# S1C31W74 register map
Vendor: Epson; Series: S1C31W74; File version: 1.11
CPU: CM0PLUS r0p1, little endian, MPU, no FPU, VTOR, 2 interrupt priority bits
Registers are 16-bit, read-write, reset 0x0 unless marked. A register's access mark holds for its fields unless they carry their own. Offsets are from the block's base; [hi:lo] are bit positions; 'fields as' and 'values as' point back to an identical list.

## USB — USB Controller
Base 0x20400000
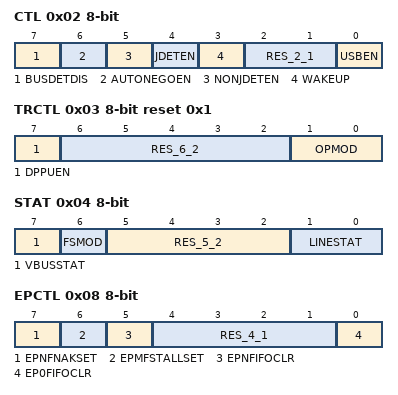
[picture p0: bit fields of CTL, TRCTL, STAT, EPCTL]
0x02 CTL 8-bit — Control Register
  [7] BUSDETDIS — USB Reset and Suspend states auto detect disable
    0=ENABLE (Enable BusDetect); 1=DISABLE (Disable BusDetect)
  [6] AUTONEGOEN — Auto-Negotiation enable
    0=DISABLE; 1=ENABLE
  [5] NONJDETEN write-1-sets — NonJ state detection enable
    0=NON (No effect); 1=ENABLE
  [4] JDETEN write-1-sets — J state detection enable
    0=NON (No effect); 1=ENABLE
  [3] WAKEUP write-1-sets — Send remote wakeup signal (K) to the USB port
    0=NON (No effect); 1=SEND (Send remote wakeup signal)
  [2:1] RES_2_1 ro — Reserved bits
  [0] USBEN — USB enable
    0=DISABLE; 1=ENABLE
0x03 TRCTL 8-bit reset 0x1 — Control Register
  [7] DPPUEN — D+ line pull-up resistor control
    0=DISABLE; 1=ENABLE
  [6:2] RES_6_2 ro — Reserved bits
  [1:0] OPMOD — Transceiver macro operation mode
    0=NORMAL (Normal operation); 1=NON_DRIVING; 2=DIS_BITSTUF_NRZI (Disable bit stuffing and NRZI encoding)
0x04 STAT 8-bit — Status Register
  [7] VBUSSTAT ro — USBVBUS pin status
    0=LOW (VBUS = L); 1=HIGH (VBUS = H)
  [6] FSMOD ro — FS mode support
    1=SUPPORTED (FS mode)
  [5:2] RES_5_2 ro — Reserved bits
  [1:0] LINESTAT ro — USB cable (value received by the FS receiver of the DP/DM) signal status
    0=SE0 (Single Ended Zero state); 1=J (J state); 2=K (K state); 3=SE1 (Single Ended One state)
0x08 EPCTL 8-bit — Endpoint Control Register
  [7] EPNFNAKSET wo write-1-sets — Endpoint ForceNAK bit
    0=NON (No effect); 1=SET (Set all ForceNAK)
  [6] EPMFSTALLSET wo write-1-sets — Endpoint ForceSTALL bit
    0=NON (No effect); 1=SET (Set all ForceSTALL)
  [5] EPNFIFOCLR wo write-1-sets — Endpoint FIFO clear
    0=NON (No effect); 1=CLEAR (Clear FIFO)
  [4:1] RES_4_1 ro — Reserved bits
  [0] EP0FIFOCLR wo write-1-sets — Endpoint EP0 FIFO clear
    0=NON (No effect); 1=CLEAR (Clear EP0 FIFO)
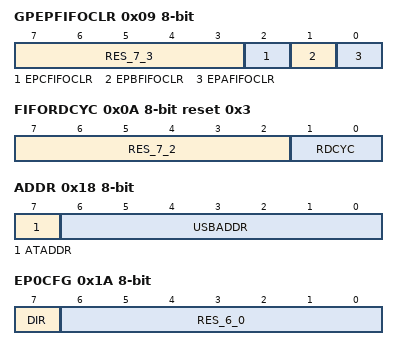
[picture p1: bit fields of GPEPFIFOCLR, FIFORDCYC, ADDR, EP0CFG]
0x09 GPEPFIFOCLR 8-bit — Endpoint Control Register
  [7:3] RES_7_3 ro — Reserved bits
  [2] EPCFIFOCLR wo write-1-sets — Endpoint EPc FIFO clear
    0=NON (No effect); 1=CLEAR (Clear EPc FIFO)
  [1] EPBFIFOCLR wo write-1-sets — Endpoint EPb FIFO clear
    0=NON (No effect); 1=CLEAR (Clear EPb FIFO)
  [0] EPAFIFOCLR wo write-1-sets — Endpoint EPa FIFO clear
    0=NON (No effect); 1=CLEAR (Clear EPa FIFO)
0x0A FIFORDCYC 8-bit reset 0x3 — FIFO Read Cycle Setup Register
  [7:2] RES_7_2 ro — Reserved bits
  [1:0] RDCYC — FIFO read access cycles
    0=1_CYC (1 cycle); 1=2_CYC (2 cycles); 2=3_CYC (3 cycles); 3=4_CYC (4 cycles)
0x0E REV 8-bit ro — Revision Number Register
  [7:0] REVNUM — USB controller revision number
0x10 EP0SETUP0 8-bit ro — EP0 Setup Data Register 0
  [7:0] BMREQTYP — Endpoint EP0 SETUP stage received BmRequestType
0x11 EP0SETUP1 8-bit ro — EP0 Setup Data Register 1
  [7:0] BREQ — Endpoint EP0 SETUP stage received BRequest
0x12 EP0SETUP2 8-bit ro — EP0 Setup Data Register 2
  [7:0] WVAL — Endpoint EP0 SETUP stage received Wvalue
0x13 EP0SETUP3 8-bit ro — EP0 Setup Data Register 3
  [7:0] WVAL — Endpoint EP0 SETUP stage received Wvalue
0x14 EP0SETUP4 8-bit ro — EP0 Setup Data Register 4
  [7:0] WINDX — Endpoint EP0 SETUP stage received WIndex
0x15 EP0SETUP5 8-bit ro — EP0 Setup Data Register 5
  [7:0] WINDX — Endpoint EP0 SETUP stage received WIndex
0x16 EP0SETUP6 8-bit ro — EP0 Setup Data Register 6
  [7:0] WLEN — Endpoint EP0 SETUP stage received WLength
0x17 EP0SETUP7 8-bit ro — EP0 Setup Data Register 3
  [7:0] WLEN — Endpoint EP0 SETUP stage received WLength
0x18 ADDR 8-bit — Address Register
  [7] ATADDR write-1-sets — USB address automatic setup
    0=NON (No effect); 1=AUTO (Auto set address)
  [6:0] USBADDR — USB address
0x1A EP0CFG 8-bit — EP0 Configuration Register
  [7] DIR — Endpoint EP0 transfer direction
    0=OUT (Output); 1=IN (Input)
  [6:0] RES_6_0 ro — Reserved bits
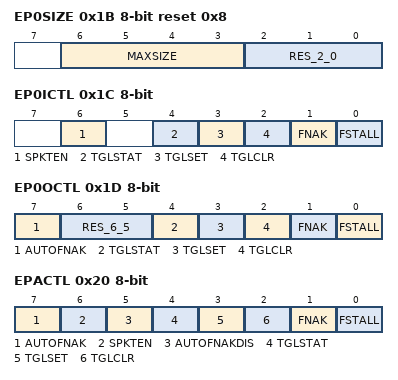
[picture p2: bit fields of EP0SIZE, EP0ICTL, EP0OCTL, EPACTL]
0x1B EP0SIZE 8-bit reset 0x8 — EP0 Configuration Size Register
  [6:3] MAXSIZE — Endpoint EP0 maximum packet size
  [2:0] RES_2_0 ro — Reserved bits
0x1C EP0ICTL 8-bit — EP0 IN Transaction Control Register
  [6] SPKTEN write-1-sets — Endpoint EP0 IN transaction short packet enable
    0=NON (No effect); 1=ENABLE (Enable short packet)
  [4] TGLSTAT ro — Endpoint EP0 IN transaction toggle sequence bit status
  [3] TGLSET wo write-1-sets — Endpoint EP0 IN transaction toggle sequence bit set
    0=NON (No effect); 1=SET (Set toggle sequence bit)
  [2] TGLCLR wo write-1-clears — Endpoint EP0 IN transaction toggle sequence bit clear
    0=NON (No effect); 1=CLEAR (Clear toggle sequence bit)
  [1] FNAK write-1-sets — Endpoint EP0 IN transaction ForceNAK
    0=NON (No effect); 1=FORCE (Force NAK)
  [0] FSTALL write-1-sets — Endpoint EP0 IN transaction ForceSTALL
    0=NON (No effect); 1=FORCE (Force STALL)
0x1D EP0OCTL 8-bit — EP0 OUT Transaction Control Register
  [7] AUTOFNAK write-1-sets — Auto ForceNAK when the OUT transaction of the endpoint EP0 completes normally
    0=NON (No effect); 1=ENABLE (Enable auto ForceNAK)
  [6:5] RES_6_5 ro — Reserved bits
  [4] TGLSTAT ro — Endpoint EP0 OUT transaction toggle sequence bit status
  [3] TGLSET wo write-1-sets — Endpoint EP0 OUT transaction toggle sequence bit set
    0=NON (No effect); 1=SET (Set toggle sequence bit)
  [2] TGLCLR wo write-1-clears — Endpoint EP0 OUT transaction toggle sequence bit clear
    0=NON (No effect); 1=CLEAR (Clear toggle sequence bit)
  [1] FNAK write-1-sets — Endpoint EP0 OUT transaction ForceNAK
    0=NON (No effect); 1=FORCE (Force NAK)
  [0] FSTALL write-1-sets — Endpoint EP0 OUT transaction ForceSTALL
    0=NON (No effect); 1=FORCE (Force STALL)
0x20 EPACTL 8-bit — EPa Control Register
  [7] AUTOFNAK write-1-sets — Auto ForceNAK when the transaction of the endpoint completes normally
    0=NON (No effect); 1=ENABLE (Enable auto ForceNAK)
  [6] SPKTEN write-1-sets — Endpoint IN transaction short packet enable
    0=NON (No effect); 1=ENABLE (Enable short packet)
  [5] AUTOFNAKDIS write-1-sets — Endpoint OUT transaction auto ForceNAK disable
    0=NON (No effect); 1=DISABLE (Disable auto ForceNAK for OUT transaction)
  [4] TGLSTAT ro — Endpoint toggle sequence bit status
  [3] TGLSET wo write-1-sets — Endpoint toggle sequence bit set
    0=NON (No effect); 1=SET (Set toggle sequence bit)
  [2] TGLCLR wo write-1-clears — Endpoint toggle sequence bit clear
    0=NON (No effect); 1=CLEAR (Clear toggle sequence bit)
  [1] FNAK write-1-sets — Endpoint ForceNAK
    0=NON (No effect); 1=FORCE (Force NAK)
  [0] FSTALL write-1-sets — Endpoint ForceSTALL
    0=NON (No effect); 1=FORCE (Force STALL)
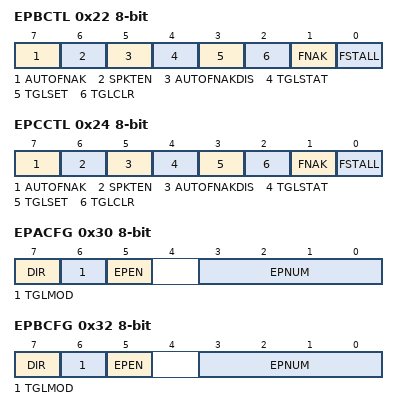
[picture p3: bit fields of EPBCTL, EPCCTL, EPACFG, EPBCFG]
0x22 EPBCTL 8-bit — EPb Control Register
  fields as EPACTL
0x24 EPCCTL 8-bit — EPc Control Register
  fields as EPACTL
0x30 EPACFG 8-bit — EPa Configuration Register
  [7] DIR — Endpoint transfer direction
    0=OUT (Output); 1=IN (Input)
  [6] TGLMOD — Endpoint toggle sequence operation mode
    0=NORMAL (Normal Toggle); 1=ALWAYS (Always Toggle)
  [5] EPEN — Endpoint enable
    0=DISABLE (Disable endPoint); 1=ENABLE (Enable endPoint)
  [3:0] EPNUM — Endpoint number
0x31 EPAMAXSZ 8-bit — EPa Size Register
  [6:0] MAXSIZE — Endpoint maximum packet size
0x32 EPBCFG 8-bit — EPb Configuration Register
  fields as EPACFG
0x33 EPBMAXSZ 8-bit — EPb Size Register
  [6:0] MAXSIZE — Endpoint maximum packet size
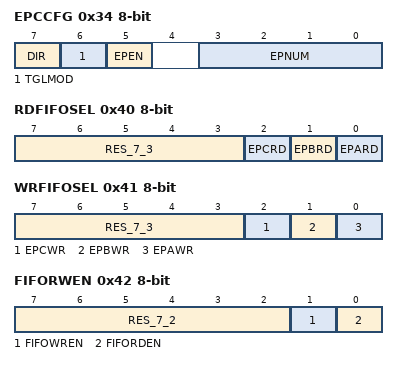
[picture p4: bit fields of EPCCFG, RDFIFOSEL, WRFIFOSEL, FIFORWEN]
0x34 EPCCFG 8-bit — EPc Configuration Register
  fields as EPACFG
0x35 EPCMAXSZ 8-bit — EPC Size Register
  [6:0] MAXSIZE — Endpoint maximum packet size
0x40 RDFIFOSEL 8-bit — Read FIFO Select Register
  [7:3] RES_7_3 ro — Reserved bits
  [2] EPCRD write-1-sets — Endpoint EPc FIFO read select
    0=NON (No effect); 1=SELECT (Select endpoint EPc for FIFO read)
  [1] EPBRD write-1-sets — Endpoint EPb FIFO read select
    0=NON (No effect); 1=SELECT (Select endpoint EPb for FIFO read)
  [0] EPARD write-1-sets — Endpoint EPa FIFO read select
    0=NON (No effect); 1=SELECT (Select endpoint EPa for FIFO read)
0x41 WRFIFOSEL 8-bit — Write FIFO Select Register
  [7:3] RES_7_3 ro — Reserved bits
  [2] EPCWR write-1-sets — Endpoint EPc FIFO write select
    0=NON (No effect); 1=SELECT (Select endpoint EPc for FIFO write)
  [1] EPBWR write-1-sets — Endpoint EPb FIFO write select
    0=NON (No effect); 1=SELECT (Select endpoint EPb for FIFO write)
  [0] EPAWR write-1-sets — Endpoint EPa FIFO write select
    0=NON (No effect); 1=SELECT (Select endpoint EPa for FIFO write)
0x42 FIFORWEN 8-bit — FIFO Read/Write Enable Register
  [7:2] RES_7_2 ro — Reserved bits
  [1] FIFOWREN write-1-sets — Endpoint FIFO write enable
    0=NON (No effect); 1=ENABLE (Enable endpoint FIFO write)
  [0] FIFORDEN write-1-sets — Endpoint FIFO read enable
    0=NON (No effect); 1=ENABLE (Enable endpoint FIFO read)
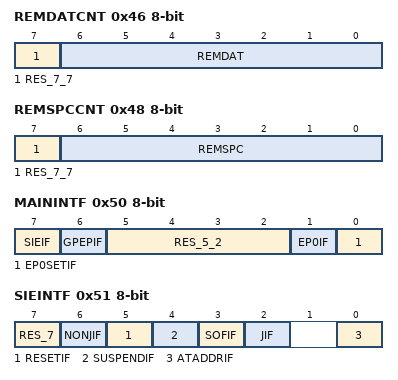
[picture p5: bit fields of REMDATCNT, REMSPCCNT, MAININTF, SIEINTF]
0x46 REMDATCNT 8-bit ro — Remaining FIFO Data Count Register
  [7] RES_7_7 — Reserved bits
  [6:0] REMDAT — FIFO remaining data count of the connected endpoint for reading
0x48 REMSPCCNT 8-bit ro — Remaining FIFO Data Space Count Register
  [7] RES_7_7 — Reserved bits
  [6:0] REMSPC — FIFO remaining space count of the connected endpoint for writing
0x4A DBGRAMADDR 8-bit — Debug RAM Address Register
  [7:0] DRAMADDR — Start address of the FIFO for debugging
0x50 MAININTF 8-bit — Main Interrupt Flag Register
  [7] SIEIF ro — Serial Interface Engine interrupt indirect status
    0=NOT_OCCURED (No cause of interrupt occurred); 1=OCCURED (Cause of interrupt occurred)
  [6] GPEPIF ro — General-purpose endpoint interrupt indirect status
    values as SIEIF
  [5:2] RES_5_2 ro — Reserved bit2
  [1] EP0IF ro — Endpoint EP0 interrupt indirect status
    values as SIEIF
  [0] EP0SETIF write-1-clears — Endpoint EP0 SETUP stage completion with received data loaded interrupt direct status
    values as SIEIF
0x51 SIEINTF 8-bit — SIE Interrupt Flag Register
  [7] RES_7 ro — VBUS is absent in new spec
  [6] NONJIF ro write-1-clears — Non J state detection interrupt direct status
    values as MAININTF.SIEIF
  [5] RESETIF ro write-1-clears — Reset state detection interrupt direct status
    values as MAININTF.SIEIF
  [4] SUSPENDIF ro write-1-clears — Suspend state detection interrupt direct status
    values as MAININTF.SIEIF
  [3] SOFIF ro write-1-clears — SOF token received interrupt direct status
    values as MAININTF.SIEIF
  [2] JIF ro write-1-clears — J state detection interrupt direct status
    values as MAININTF.SIEIF
  [0] ATADDRIF ro write-1-clears — AutoSetAddress function normal completion interrupt direct status
    values as MAININTF.SIEIF
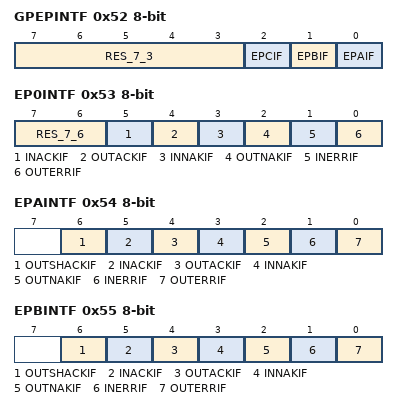
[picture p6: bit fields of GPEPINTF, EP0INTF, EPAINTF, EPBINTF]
0x52 GPEPINTF 8-bit — Gerneral Endpoint Interrupt Flag Register
  [7:3] RES_7_3 ro — Reserved bit
  [2] EPCIF ro — Endpoint EPc interrupt indirect status
    values as MAININTF.SIEIF
  [1] EPBIF ro — Endpoint EPb interrupt indirect status
    values as MAININTF.SIEIF
  [0] EPAIF ro — Endpoint EPa interrupt indirect status
    values as MAININTF.SIEIF
0x53 EP0INTF 8-bit — Endpoint Interrupt Flag Register
  [7:6] RES_7_6 ro — Reserved bits
  [5] INACKIF ro write-1-clears — Endpoint EP0 IN transaction ACK reception interrupt direct status
    values as MAININTF.SIEIF
  [4] OUTACKIF ro write-1-clears — Endpoint EP0 OUT transaction ACK sent interrupt direct status
    values as MAININTF.SIEIF
  [3] INNAKIF ro write-1-clears — Endpoint EP0 IN transaction NAK reception interrupt direct status
    values as MAININTF.SIEIF
  [2] OUTNAKIF ro write-1-clears — Endpoint EP0 OUT transaction NAK sent interrupt direct status
    values as MAININTF.SIEIF
  [1] INERRIF ro write-1-clears — Endpoint EP0 IN transaction STALL reception interrupt direct status
    values as MAININTF.SIEIF
  [0] OUTERRIF ro write-1-clears — Endpoint EP0 OUT transaction STALL sent interrupt direct status
    values as MAININTF.SIEIF
0x54 EPAINTF 8-bit — Endpoints EPa Interrupt Flag Register
  [all] fields
    values as MAININTF.SIEIF
  [6] OUTSHACKIF ro write-1-clears — Endpoint EPa short packet reception and ACK sent interrupt direct status
  [5] INACKIF ro write-1-clears — Endpoint EPa IN transaction ACK reception interrupt direct status
  [4] OUTACKIF ro write-1-clears — Endpoint EPa OUT transaction ACK sent interrupt direct status
  [3] INNAKIF ro write-1-clears — Endpoint EPa IN transaction NAK reception interrupt direct status
  [2] OUTNAKIF ro write-1-clears — Endpoint EPa OUT transaction NAK sent interrupt direct status
  [1] INERRIF ro write-1-clears — Endpoint EPa IN transaction STALL reception interrupt direct status
  [0] OUTERRIF ro write-1-clears — Endpoint EPa OUT transaction STALL sent interrupt direct status
0x55 EPBINTF 8-bit — Endpoints EPa/EPb Interrupt Flag Register
  [all] fields
    values as MAININTF.SIEIF
  [6] OUTSHACKIF ro write-1-clears — Endpoint EPb short packet reception and ACK sent interrupt direct status
  [5] INACKIF ro write-1-clears — Endpoint EPb IN transaction ACK reception interrupt direct status
  [4] OUTACKIF ro write-1-clears — Endpoint EPb OUT transaction ACK sent interrupt direct status
  [3] INNAKIF ro write-1-clears — Endpoint EPb IN transaction NAK reception interrupt direct status
  [2] OUTNAKIF ro write-1-clears — Endpoint EPb OUT transaction NAK sent interrupt direct status
  [1] INERRIF ro write-1-clears — Endpoint EPb IN transaction STALL reception interrupt direct status
  [0] OUTERRIF ro write-1-clears — Endpoint EPb OUT transaction STALL sent interrupt direct status
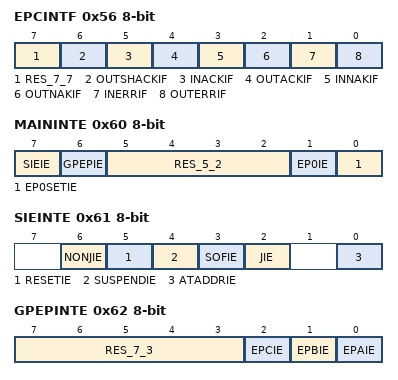
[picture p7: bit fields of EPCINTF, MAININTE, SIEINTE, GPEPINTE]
0x56 EPCINTF 8-bit — Endpoints EPc Interrupt Flag Register
  [7] RES_7_7 ro — Reserved bits
  [6] OUTSHACKIF ro write-1-clears — Endpoint EPc short packet reception and ACK sent interrupt direct status
    values as MAININTF.SIEIF
  [5] INACKIF ro write-1-clears — Endpoint EPc IN transaction ACK reception interrupt direct status
    values as MAININTF.SIEIF
  [4] OUTACKIF ro write-1-clears — Endpoint EPc OUT transaction ACK sent interrupt direct status
    values as MAININTF.SIEIF
  [3] INNAKIF ro write-1-clears — Endpoint EPc IN transaction NAK reception interrupt direct status
    values as MAININTF.SIEIF
  [2] OUTNAKIF ro write-1-clears — Endpoint EPc OUT transaction NAK sent interrupt direct status
    values as MAININTF.SIEIF
  [1] INERRIF ro write-1-clears — Endpoint EPc IN transaction STALL reception interrupt direct status
    values as MAININTF.SIEIF
  [0] OUTERRIF ro write-1-clears — Endpoint EPc OUT transaction STALL sent interrupt direct status
    values as MAININTF.SIEIF
0x60 MAININTE 8-bit — Main Interrupt Enable Register
  [7] SIEIE — Serial Interface Engine interrupt enable
    0=DISABLE (Disable interrupt); 1=ENABLE (Enable interrupt)
  [6] GPEPIE — General-purpose endpoint interrupt enable
    0=DISABLE (Disable interrupt); 1=ENABLE (Enable interrupt)
  [5:2] RES_5_2 ro — Reserved bit2
  [1] EP0IE — Endpoint EP0 interrupt enable
    0=DISABLE (Disable interrupt); 1=ENABLE (Enable interrupt)
  [0] EP0SETIE — Endpoint EP0 SETUP stage completion with received data loaded interrupt enable
    0=DISABLE (Disable interrupt); 1=ENABLE (Enable interrupt)
0x61 SIEINTE 8-bit — SIE Interrupt Enable Register
  [all] fields
    0=DISABLE (Disable interrupt); 1=ENABLE (Enable interrupt)
  [6] NONJIE — Non J state detection interrupt enable
  [5] RESETIE — Reset state detection interrupt enable
  [4] SUSPENDIE — Suspend state detection interrupt enable
  [3] SOFIE — SOF token received interrupt enable
  [2] JIE — J state detection interrupt enable
  [0] ATADDRIE — AutoSetAddress function normal completion interrupt enable
0x62 GPEPINTE 8-bit — General Purpose Endpoint Interrupt Enable Register
  [7:3] RES_7_3 ro — Reserved bit
  [2] EPCIE — Endpoint EPc interrupt enable
    0=DISABLE (Disable interrupt); 1=ENABLE (Enable interrupt)
  [1] EPBIE — Endpoint EPb interrupt enable
    0=DISABLE (Disable interrupt); 1=ENABLE (Enable interrupt)
  [0] EPAIE — Endpoint EPa interrupt enable
    0=DISABLE (Disable interrupt); 1=ENABLE (Enable interrupt)
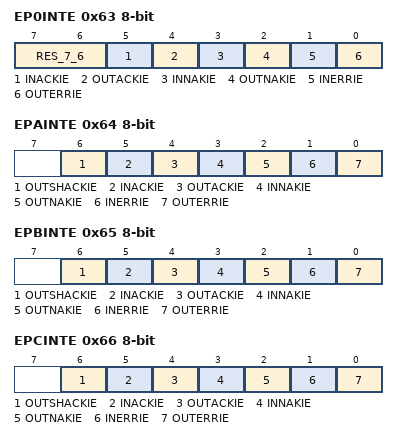
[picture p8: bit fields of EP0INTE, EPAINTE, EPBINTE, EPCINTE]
0x63 EP0INTE 8-bit — Endpoint Interrupt Enable Register
  [7:6] RES_7_6 ro — Reserved bits
  [5] INACKIE — Endpoint EP0 IN transaction ACK reception interrupt enable
    0=DISABLE (Disable interrupt); 1=ENABLE (Enable interrupt)
  [4] OUTACKIE — Endpoint EP0 OUT transaction ACK sent interrupt enable
    0=DISABLE (Disable interrupt); 1=ENABLE (Enable interrupt)
  [3] INNAKIE — Endpoint EP0 IN transaction NAK reception interrupt enable
    0=DISABLE (Disable interrupt); 1=ENABLE (Enable interrupt)
  [2] OUTNAKIE — Endpoint EP0 OUT transaction NAK sent interrupt enable
    0=DISABLE (Disable interrupt); 1=ENABLE (Enable interrupt)
  [1] INERRIE — Endpoint EP0 IN transaction STALL reception interrupt enable
    0=DISABLE (Disable interrupt); 1=ENABLE (Enable interrupt)
  [0] OUTERRIE — Endpoint EP0 OUT transaction STALL sent interrupt enable
    0=DISABLE (Disable interrupt); 1=ENABLE (Enable interrupt)
0x64 EPAINTE 8-bit — Endpoints EPa Interrupt Enable Register
  [all] fields
    0=DISABLE (Disable interrupt); 1=ENABLE (Enable interrupt)
  [6] OUTSHACKIE — Endpoint EPa short packet reception and ACK sent interrupt enable
  [5] INACKIE — Endpoint EPa IN transaction ACK reception interrupt enable
  [4] OUTACKIE — Endpoint EPa OUT transaction ACK sent interrupt enable
  [3] INNAKIE — Endpoint EPa IN transaction NAK reception interrupt enable
  [2] OUTNAKIE — Endpoint EPa OUT transaction NAK sent interrupt enable
  [1] INERRIE — Endpoint EPa IN transaction STALL reception interrupt enable
  [0] OUTERRIE — Endpoint EPa OUT transaction STALL sent interrupt enable
0x65 EPBINTE 8-bit — Endpoints EPb Interrupt Enable Register
  [all] fields
    0=DISABLE (Disable interrupt); 1=ENABLE (Enable interrupt)
  [6] OUTSHACKIE — Endpoint EPb short packet reception and ACK sent interrupt enable
  [5] INACKIE — Endpoint EPb IN transaction ACK reception interrupt enable
  [4] OUTACKIE — Endpoint EPb OUT transaction ACK sent interrupt enable
  [3] INNAKIE — Endpoint EPb IN transaction NAK reception interrupt enable
  [2] OUTNAKIE — Endpoint EPb OUT transaction NAK sent interrupt enable
  [1] INERRIE — Endpoint EPb IN transaction STALL reception interrupt enable
  [0] OUTERRIE — Endpoint EPb OUT transaction STALL sent interrupt enable
0x66 EPCINTE 8-bit — Endpoints EPc Interrupt Enable Register
  [all] fields
    0=DISABLE (Disable interrupt); 1=ENABLE (Enable interrupt)
  [6] OUTSHACKIE — Endpoint EPc short packet reception and ACK sent interrupt enable
  [5] INACKIE — Endpoint EPc IN transaction ACK reception interrupt enable
  [4] OUTACKIE — Endpoint EPc OUT transaction ACK sent interrupt enable
  [3] INNAKIE — Endpoint EPc IN transaction NAK reception interrupt enable
  [2] OUTNAKIE — Endpoint EPc OUT transaction NAK sent interrupt enable
  [1] INERRIE — Endpoint EPc IN transaction STALL reception interrupt enable
  [0] OUTERRIE — Endpoint EPc OUT transaction STALL sent interrupt enable
0x100 FIFODAT 8-bit — FIFO Data Register
  [7:0] FIFODAT — FIFO data access
0x104 DBGRAMDAT 8-bit — Debug RAM Data Register
  [7:0] DBRAMDAT — FIFO data access for debugging
